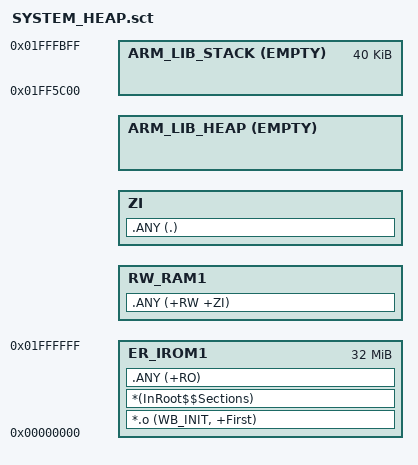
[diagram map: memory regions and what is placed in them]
LR_IROM1 0x00000000 0x02000000
{
    ER_IROM1 0x00000000 0x02000000
    {
        *.o (WB_INIT, +First)
        *(InRoot$$Sections)
        .ANY (+RO)
    }
    RW_RAM1 +0
    {
        .ANY (+RW +ZI)
    }
    ZI +0
    {
        .ANY (.)
    }
    ARM_LIB_HEAP +0 ALIGN 32 EMPTY (0x01FF5C00 - AlignExpr(ImageLimit(ZI), 32))
    {
    }
    ARM_LIB_STACK 0x01FFFC00 EMPTY -0xA000
    {
    }
    ScatterAssert(AlignExpr(ImageLimit(ZI), 32) <= 0x01FF5C00)
}
